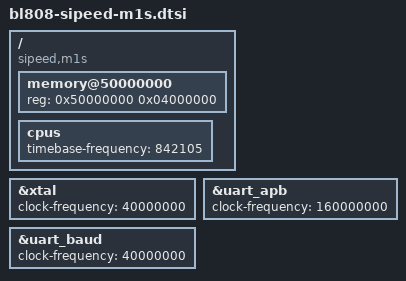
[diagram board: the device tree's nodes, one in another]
// SPDX-License-Identifier: (GPL-2.0+ OR MIT)

#include "bl808.dtsi"

/ {
	compatible = "sipeed,m1s", "bouffalolab,bl808";
	memory@50000000 {
		device_type = "memory";
		reg = <0x50000000 0x04000000>;
	};

	cpus {
		timebase-frequency = <842105>;
	};
};

&xtal {
	clock-frequency = <40000000>;
};

/* Rates supplied by the current M1s boot firmware. */
&uart_apb {
	clock-frequency = <160000000>;
};

&uart_baud {
	clock-frequency = <40000000>;
};
